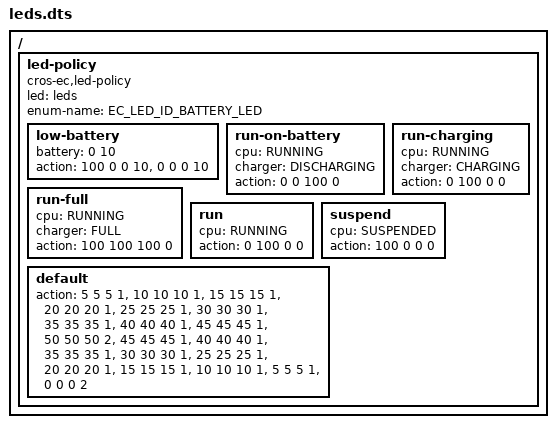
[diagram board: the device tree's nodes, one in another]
/* Copyright 2022 The Chromium OS Authors. All rights reserved.
 * Use of this source code is governed by a BSD-style license that can be
 * found in the LICENSE file.
 */

/ {
	/*
	 * Mapping of inputs to LED actions
	 */
	led-policy {
		compatible = "cros-ec,led-policy";

		led = <&leds>;
		enum-name = "EC_LED_ID_BATTERY_LED";

		low-battery {
			battery = <0 10>;
			/* Flashing red */
			action = <100 0 0 10>,
				 <0 0 0 10>;
		};
		run-on-battery {
			cpu = "RUNNING";
			charger = "DISCHARGING";
			/* Solid blue */
			action = <0 0 100 0>;
		};
		run-charging {
			cpu = "RUNNING";
			charger = "CHARGING";
			/* Solid green */
			action = <0 100 0 0>;
		};
		run-full {
			cpu = "RUNNING";
			charger = "FULL";
			/* Solid white */
			action = <100 100 100 0>;
		};
		run {
			cpu = "RUNNING";
			/* Solid green */
			action = <0 100 0 0>;
		};
		suspend {
			cpu = "SUSPENDED";
			/* Solid red */
			action = <100 0 0 0>;
		};
		default {
			/* White fade in and out */
			action = <5 5 5 1>, <10 10 10 1>, <15 15 15 1>,
				 <20 20 20 1>, <25 25 25 1>, <30 30 30 1>,
				 <35 35 35 1>, <40 40 40 1>, <45 45 45 1>,
				 <50 50 50 2>,
				 <45 45 45 1>, <40 40 40 1>, <35 35 35 1>,
				 <30 30 30 1>, <25 25 25 1>, <20 20 20 1>,
				 <15 15 15 1>, <10 10 10 1>, <5 5 5 1>,
				 <0 0 0 2>;
		};
	};
};
